# STM32G431xx register map
File version: 1.0
CPU: CM4 r0p1, little endian, MPU, FPU, 4 interrupt priority bits
Registers are 32-bit, read-write, reset 0x0 unless marked. A register's access mark holds for its fields unless they carry their own. Offsets are from the block's base; [hi:lo] are bit positions; {n}, {i} and the like mark numbered series; 'fields as' and 'values as' point back to an identical list.

## SAI — Serial audio interface
Base 0x40015400
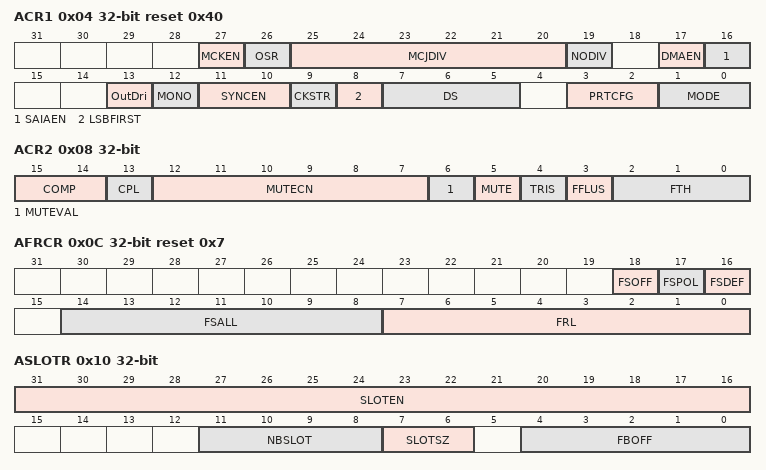
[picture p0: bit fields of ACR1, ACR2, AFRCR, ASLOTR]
0x04 ACR1 reset 0x40 — AConfiguration register 1
  [27] MCKEN
  [26] OSR
  [25:20] MCJDIV — Master clock divider
  [19] NODIV — No divider
  [17] DMAEN — DMA enable
  [16] SAIAEN — Audio block A enable
  [13] OutDri — Output drive
  [12] MONO — Mono mode
  [11:10] SYNCEN — Synchronization enable
  [9] CKSTR — Clock strobing edge
  [8] LSBFIRST — Least significant bit first
  [7:5] DS — Data size
  [3:2] PRTCFG — Protocol configuration
  [1:0] MODE — Audio block mode
0x08 ACR2 — AConfiguration register 2
  [15:14] COMP — Companding mode
  [13] CPL — Complement bit
  [12:7] MUTECN — Mute counter
  [6] MUTEVAL — Mute value
  [5] MUTE
  [4] TRIS — Tristate management on data line
  [3] FFLUS — FIFO flush
  [2:0] FTH — FIFO threshold
0x0C AFRCR reset 0x7
  [18] FSOFF — Frame synchronization offset
  [17] FSPOL — Frame synchronization polarity
  [16] FSDEF — Frame synchronization definition
  [14:8] FSALL — Frame synchronization active level length
  [7:0] FRL — Frame length
0x10 ASLOTR — ASlot register
  [31:16] SLOTEN — Slot enable
  [11:8] NBSLOT — Number of slots in an audio frame
  [7:6] SLOTSZ — Slot size
  [4:0] FBOFF — First bit offset
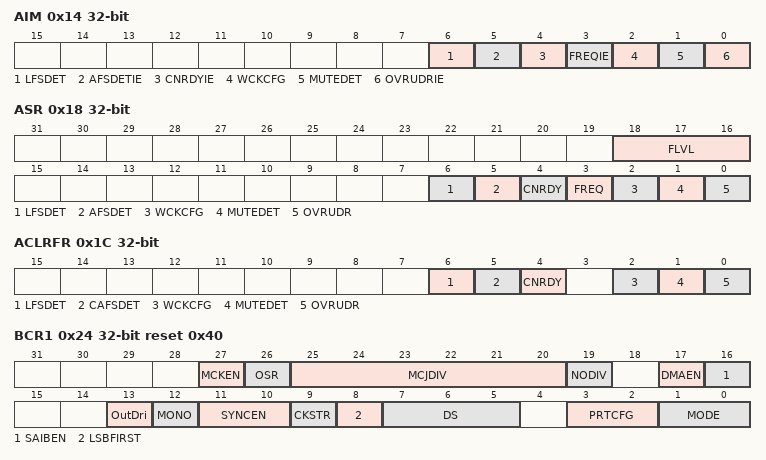
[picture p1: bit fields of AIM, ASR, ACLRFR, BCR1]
0x14 AIM — AInterrupt mask register2
  [6] LFSDET — Late frame synchronization detection interrupt enable
  [5] AFSDETIE — Anticipated frame synchronization detection interrupt enable
  [4] CNRDYIE — Codec not ready interrupt enable
  [3] FREQIE — FIFO request interrupt enable
  [2] WCKCFG — Wrong clock configuration interrupt enable
  [1] MUTEDET — Mute detection interrupt enable
  [0] OVRUDRIE — Overrun/underrun interrupt enable
0x18 ASR — AStatus register
  [18:16] FLVL — FIFO level threshold
  [6] LFSDET — Late frame synchronization detection
  [5] AFSDET — Anticipated frame synchronization detection
  [4] CNRDY — Codec not ready
  [3] FREQ — FIFO request
  [2] WCKCFG — Wrong clock configuration flag. This bit is read only
  [1] MUTEDET — Mute detection
  [0] OVRUDR — Overrun / underrun
0x1C ACLRFR — AClear flag register
  [6] LFSDET — Clear late frame synchronization detection flag
  [5] CAFSDET — Clear anticipated frame synchronization detection flag
  [4] CNRDY — Clear codec not ready flag
  [2] WCKCFG — Clear wrong clock configuration flag
  [1] MUTEDET — Mute detection flag
  [0] OVRUDR — Clear overrun / underrun
0x20 ADR — AData register
  [31:0] DATA
0x24 BCR1 reset 0x40 — BConfiguration register 1
  [27] MCKEN
  [26] OSR
  [25:20] MCJDIV — Master clock divider
  [19] NODIV — No divider
  [17] DMAEN — DMA enable
  [16] SAIBEN — Audio block B enable
  [13] OutDri — Output drive
  [12] MONO — Mono mode
  [11:10] SYNCEN — Synchronization enable
  [9] CKSTR — Clock strobing edge
  [8] LSBFIRST — Least significant bit first
  [7:5] DS — Data size
  [3:2] PRTCFG — Protocol configuration
  [1:0] MODE — Audio block mode
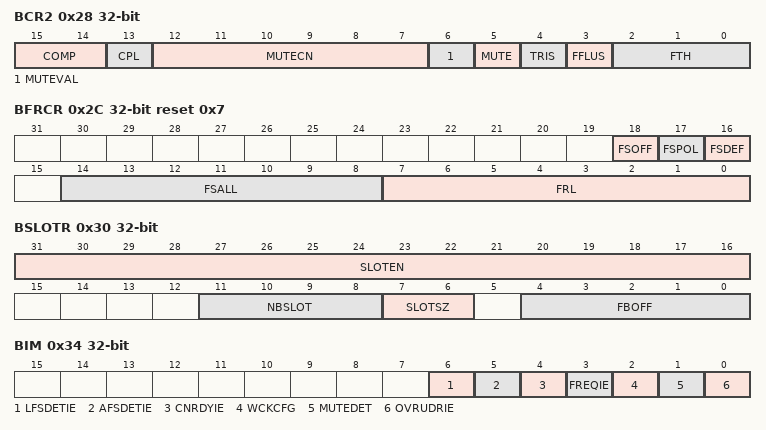
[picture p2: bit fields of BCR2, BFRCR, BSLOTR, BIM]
0x28 BCR2 — BConfiguration register 2
  fields as ACR2
0x2C BFRCR reset 0x7
  fields as AFRCR
0x30 BSLOTR — BSlot register
  fields as ASLOTR
0x34 BIM — BInterrupt mask register2
  [6] LFSDETIE — Late frame synchronization detection interrupt enable
  [5] AFSDETIE — Anticipated frame synchronization detection interrupt enable
  [4] CNRDYIE — Codec not ready interrupt enable
  [3] FREQIE — FIFO request interrupt enable
  [2] WCKCFG — Wrong clock configuration interrupt enable
  [1] MUTEDET — Mute detection interrupt enable
  [0] OVRUDRIE — Overrun/underrun interrupt enable
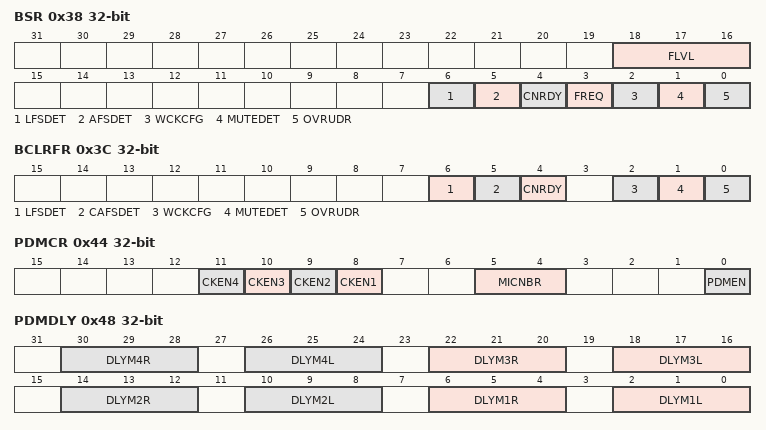
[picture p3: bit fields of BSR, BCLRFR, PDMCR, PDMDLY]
0x38 BSR ro — BStatus register
  [18:16] FLVL — FIFO level threshold
  [6] LFSDET — Late frame synchronization detection
  [5] AFSDET — Anticipated frame synchronization detection
  [4] CNRDY — Codec not ready
  [3] FREQ — FIFO request
  [2] WCKCFG — Wrong clock configuration flag
  [1] MUTEDET — Mute detection
  [0] OVRUDR — Overrun / underrun
0x3C BCLRFR wo — BClear flag register
  fields as ACLRFR
0x40 BDR — BData register
  [31:0] DATA
0x44 PDMCR — PDM control register
  [n+7] CKEN{n} (n=1..4), [5:4] MICNBR, [0] PDMEN
0x48 PDMDLY — PDM delay register
  [8n-2:8n-4] DLYM{n}R (n=1..4), [8n-6:8n-8] DLYM{n}L (n=1..4)
